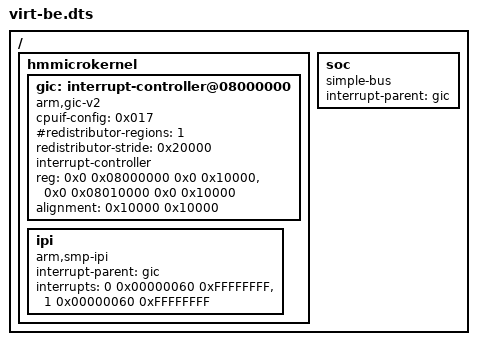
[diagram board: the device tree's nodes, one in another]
/dts-v1/;

/ {
	#address-cells = <2>;
	#size-cells = <2>;

	hmmicrokernel {
		#address-cells = <2>;
		#size-cells = <2>;

		gic: interrupt-controller@08000000 {
			compatible = "arm,gic-v2";

			#address-cells = <2>;
			#size-cells = <2>;

			/* enable group 0 & 1, set ActCtl and CBPR,
			 * not enable irq, no split EOI mode
			 */
			cpuif-config = <0x017>;

			#interrupt-cells = <3>;
			#redistributor-regions = <1>;
			redistributor-stride = <0x20000>;
			interrupt-controller;
			reg =	<0x0 0x08000000 0x0 0x10000>,	/* GICD */
				<0x0 0x08010000 0x0 0x10000>;	/* GICC */
			alignment = <0x10000 0x10000>;
		};

		ipi {
			/* smp ipi */
			compatible = "arm,smp-ipi";

			interrupt-parent = <&gic>;

			/* interrupt settings:
			 * 1st cell: real hardware irq number
			 *     ARM recommendation: ID 0-7 for Non-Secure;
			 *                         ID 8-15 for Secure Interrupt
			 * 2nd cell: interrupt config
			 *     bit [27:26]: Group setting
			 *     bit [24]: Trigger Type
			 *     bit [7:0]: Priority
			 * 3rd cell: interrupt target config
			 *     Warning: Send to all cpus by default
			 */
			interrupts =	<0 0x00000060 0xFFFFFFFF>, /* IPI_RESCHEDULE */
					<1 0x00000060 0xFFFFFFFF>; /* IPI_CALL_FUNC */
		};

	};

	soc {
		compatible = "simple-bus";
		#address-cells = <2>;
		#size-cells = <2>;
		ranges;
		interrupt-parent = <&gic>;
	};
};

/include/ "virtio.dtsi"
/include/ "virt-common.dtsi"
